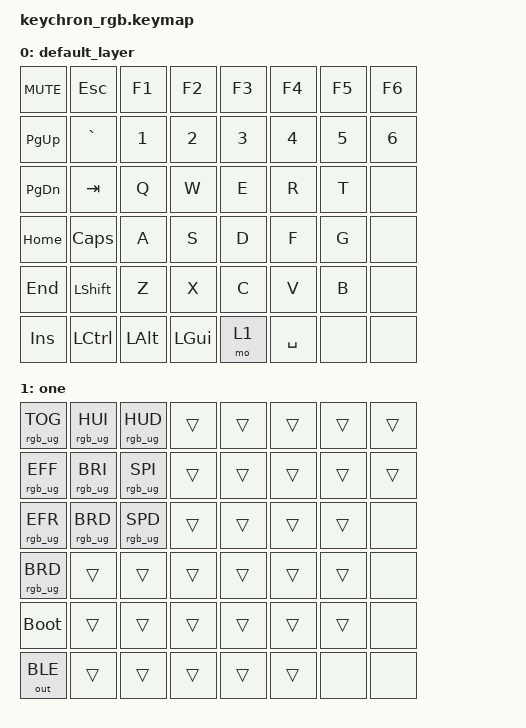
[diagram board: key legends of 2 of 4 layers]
/*
 * Copyright (c) 2020 The ZMK Contributors
 *
 * SPDX-License-Identifier: MIT
 */

#include <behaviors.dtsi>
#include <dt-bindings/zmk/keys.h>
#include <dt-bindings/zmk/bt.h>
#include <dt-bindings/zmk/outputs.h>
#include <dt-bindings/zmk/rgb.h>
/ {
    keymap {
            compatible = "zmk,keymap";
            default_layer {
                bindings = <
                    &kp K_MUTE  &kp ESC     &kp F1      &kp F2      &kp F3      &kp F4      &kp F5  &kp F6
                    &kp PG_UP   &kp GRAVE   &kp N1      &kp N2      &kp N3      &kp N4      &kp N5  &kp N6
                    &kp PG_DN   &kp TAB     &kp Q       &kp W       &kp E       &kp R       &kp T   &none
                    &kp HOME    &kp CLCK    &kp A       &kp S       &kp D       &kp F       &kp G   &none
                    &kp END     &kp LSHFT   &kp Z       &kp X       &kp C       &kp V       &kp B   &none
                    &kp INS     &kp LCTRL   &kp LALT    &kp LGUI    &mo 1       &kp SPACE   &none   &none
                >;
                sensor-bindings = <&inc_dec_kp C_VOL_UP C_VOL_DN>;
            };
            one {
                bindings = <
                    &rgb_ug RGB_TOG           &rgb_ug  RGB_HUI      &rgb_ug  RGB_HUD       &trans       &trans      &trans      &trans  &trans
                    &rgb_ug  RGB_EFF          &rgb_ug  RGB_BRI      &rgb_ug RGB_SPI        &trans       &trans      &trans      &trans  &trans
                    &rgb_ug  RGB_EFR          &rgb_ug  RGB_BRD      &rgb_ug RGB_SPD        &trans       &trans      &trans      &trans  &none
                    &rgb_ug  RGB_BRD          &trans                &trans                 &trans       &trans      &trans      &trans  &none
                    &bootloader               &trans                &trans                 &trans       &trans      &trans      &trans  &none
                    &out OUT_BLE              &trans                &trans                 &trans       &trans      &trans      &none   &none
                >;
            };
            two {
                bindings = <
                    &kp K_MUTE  &kp ESC     &kp F1      &kp F2      &kp F3      &kp F4      &kp F5  &kp F6
                    &kp PG_UP   &kp GRAVE   &kp N1      &kp N2      &kp N3      &kp N4      &kp N5  &kp N6
                    &kp PG_DN   &kp TAB     &kp Q       &kp W       &kp E       &kp R       &kp T
                    &kp HOME    &kp CLCK    &kp A       &kp S       &kp D       &kp F       &kp G
                    &kp END     &kp LSHFT   &kp Z       &kp X       &kp C       &kp V       &kp B
                    &kp INS     &kp LCTRL   &kp LALT    &kp LGUI    &mo 1       &kp SPACE
                >;
            };
            three {
                bindings = <
                    &trans      &trans      &trans      &trans       &trans      &trans      &trans  &trans
                    &trans      &trans      &trans      &trans       &trans      &trans      &trans  &trans
                    &trans      &trans      &trans      &trans       &trans      &trans      &trans
                    &trans      &trans      &trans      &trans       &trans      &trans      &trans
                    &trans      &trans      &trans      &trans       &trans      &trans      &trans
                    &trans      &trans      &trans      &trans       &trans      &trans
                >;
            };
            
    };
};

